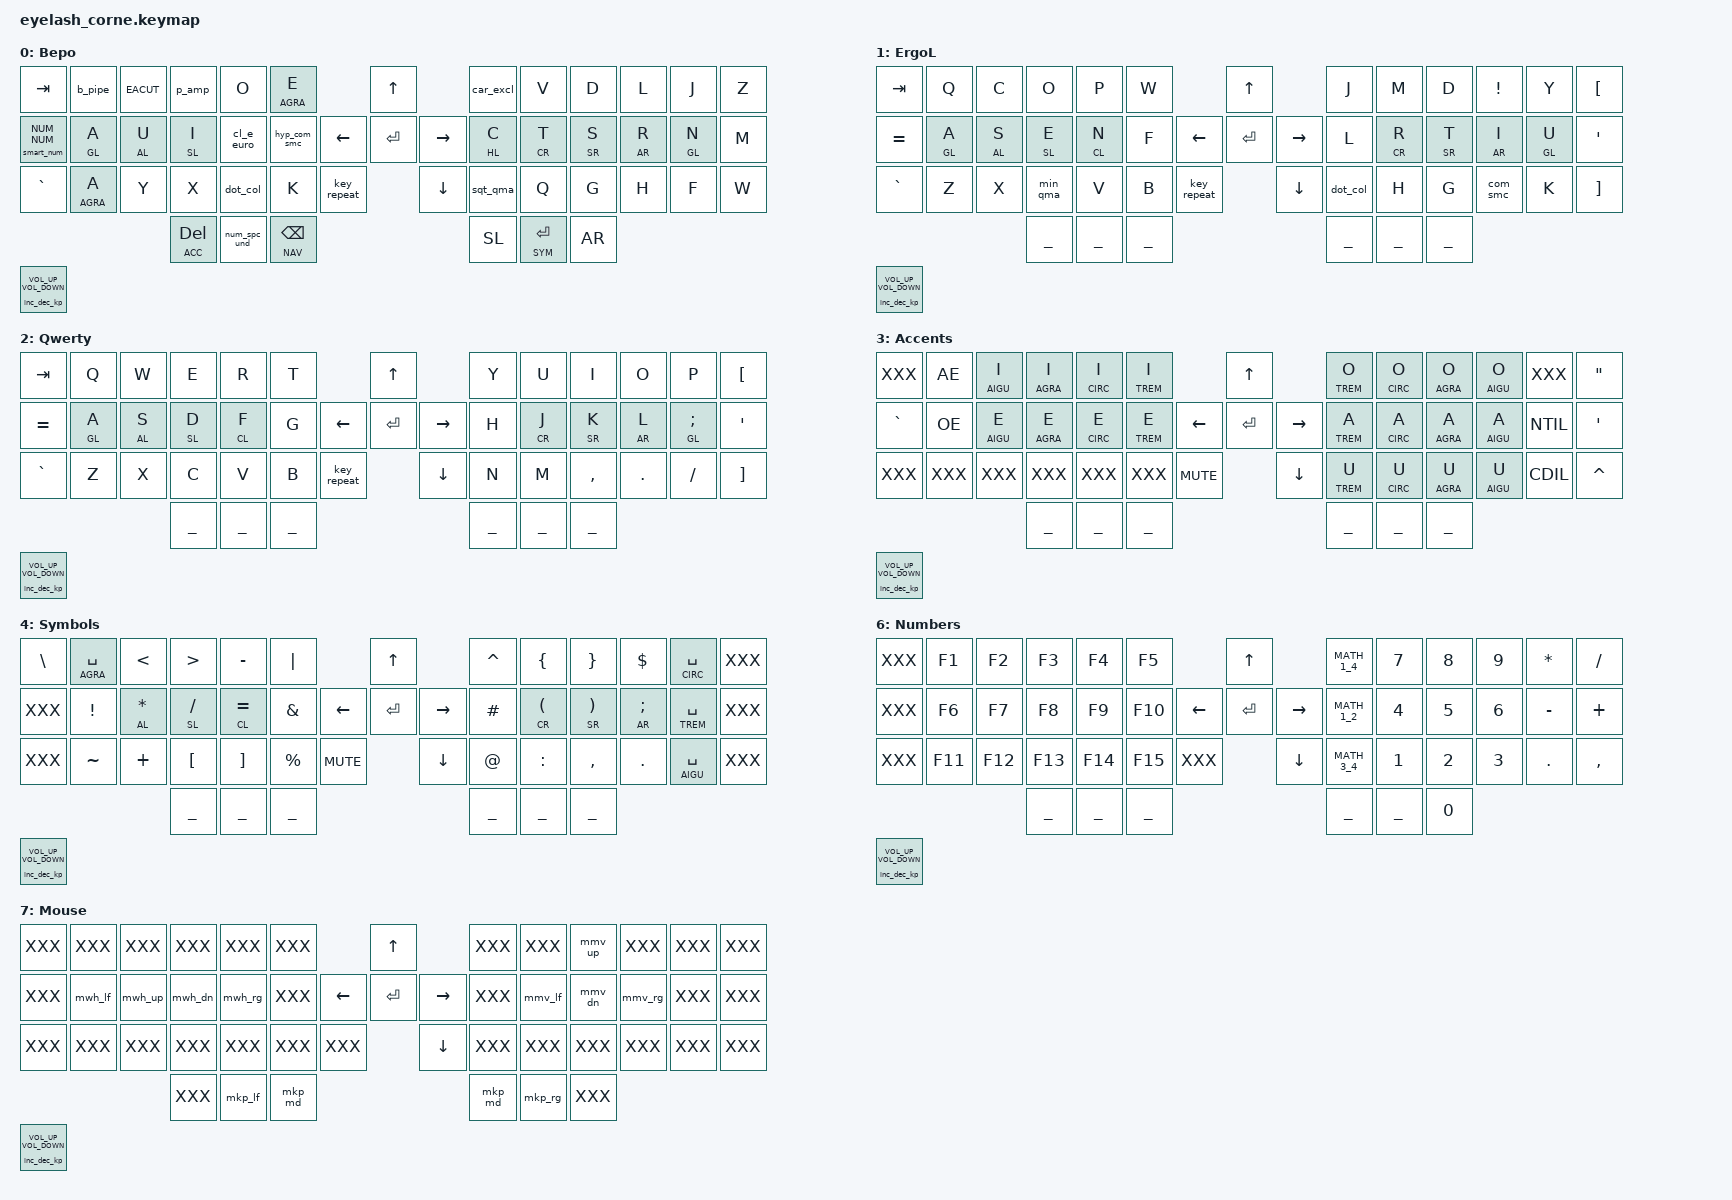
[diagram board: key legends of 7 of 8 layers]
#include <dt-bindings/zmk/mouse.h>
#include <input/processors.dtsi>
#include <behaviors.dtsi>
#include <dt-bindings/zmk/bt.h>
#include <dt-bindings/zmk/keys.h>
#include <dt-bindings/zmk/outputs.h>
#include <dt-bindings/zmk/pointing.h>
#include <dt-bindings/zmk/rgb.h>

#include "constants.h"
#define HOST_OS LINUX // Needed for unicode international_chars

#include "zmk-helpers/helper.h"
#include "zmk-helpers/key-labels/eyelash42.h"
#include "zmk-helpers/unicode-chars/currency.dtsi"
#include "zmk-helpers/unicode-chars/french.dtsi"
#include "combos.dtsi"
#include "leader.dtsi"
#include "numword.dtsi"
#include "hold-tap.dtsi"
#include "mod-morph.dtsi"
#include "mouse.dtsi"

#define ZMK_MOUSE_DEFAULT_MOVE_VAL 1200  // 600
#define ZMK_MOUSE_DEFAULT_SCRL_VAL 20    // 10
#define IDLE_MS 125


// 0: Bépo
// This is an "adaptation" of the bépo layout (https://bepo.fr/wiki/Accueil)
// There is some difference
// - No Ê or Ç keys, we don't have enough room
// - Not all RIGHT_ALT and RIGHT_ALT+SHIFT are available, as those might be accessed from a different layer instead, and some are very hard to do, like `…`
// - It works if the layout on the system (at least for that keyboard) is US_intl 😇. This is common enough (and available everywhere, Linux, Windows, OSX, Android, …)
// - TODO go to accent layer (and back)
ZMK_LAYER(Bepo,
// ╭───────────┬───────────┬───────────┬───────────┬────────────┬────────────╮                                ╭───────────┬─────────────┬─────────────┬────────────┬────────────┬────────────╮
     &kp TAB     &b_pipe     &kp EACUT   &p_amp      &kp O        &AGRA E                 &kp UP                &car_excl   &kp V         &kp D         &kp L        &kp J        &kp Z
// ├───────────┼───────────┼───────────┼───────────┼────────────┼────────────┤                                ├───────────┼─────────────┼─────────────┼────────────┼────────────┼────────────┤
     &smart_num NUM NUM   &hml GL A   &hml AL U   &hml SL I   &cl_e_euro   &hyp_com_smc  &kp LEFT  &kp RET  &kp RIGHT    &hmr HL C   &hmr CR T     &hmr SR S     &hmr AR R    &hmr GL N    &kp M
// ├───────────┼───────────┼───────────┼───────────┼────────────┼────────────┤                                ├───────────┼─────────────┼─────────────┼────────────┼────────────┼────────────┤
     &kp GRAVE   &AGRA A     &kp Y       &kp X       &dot_col     &kp K        &key_repeat &kp DOWN          &sqt_qma    &kp Q         &kp G         &kp H        &kp F        &kp W
// ╰───────────┴───────────────────────┼───────────┼────────────┼────────────┤                                ├───────────┼─────────────┼─────────────┼────────────┴────────────┴────────────╯
                                        &lt ACC DEL  &num_spc_und &lt NAV BSPC                                   &kp SL      &lt SYM RET   &kp AR
//                                     ╰───────────┴────────────┴────────────╯                                ╰───────────┴─────────────┴─────────────╯
	  , &inc_dec_kp C_VOLUME_UP C_VOLUME_DOWN
)

// 1: ErgoL
// This is an "adaptation" of the ergol layout (https://ergol.org/claviers/compacts/#kbd_3x6)
ZMK_LAYER(ErgoL,
// ╭───────────┬───────────┬───────────┬───────────┬────────────┬────────────╮                                ╭───────────┬─────────────┬─────────────┬────────────┬────────────┬────────────╮
     &kp TAB     &kp Q       &kp C       &kp O       &kp P        &kp  W                  &kp UP                &kp J       &kp M         &kp D         &kp EXCL     &kp Y        &kp LBKT
// ├───────────┼───────────┼───────────┼───────────┼────────────┼────────────┤                                ├───────────┼─────────────┼─────────────┼────────────┼────────────┼────────────┤
     &kp EQUAL   &hml GL A   &hml AL S   &hml SL E   &hml CL N    &kp F         &kp LEFT  &kp RET  &kp RIGHT    &kp L       &hmr CR R     &hmr SR T     &hmr AR I    &hmr GL U    &kp SQT
// ├───────────┼───────────┼───────────┼───────────┼────────────┼────────────┤                                ├───────────┼─────────────┼─────────────┼────────────┼────────────┼────────────┤
     &kp GRAVE   &kp Z       &kp X       &min_qma    &kp V        &kp B        &key_repeat &kp DOWN          &dot_col    &kp H         &kp G         &com_smc     &kp K        &kp RBKT
// ╰───────────┴───────────────────────┼───────────┼────────────┼────────────┤                                ├───────────┼─────────────┼─────────────┼────────────┴────────────┴────────────╯
                                         ___         ___          ___                                           ___         ___           ___
//                                     ╰───────────┴────────────┴────────────╯                                ╰───────────┴─────────────┴─────────────╯
	  , &inc_dec_kp C_VOLUME_UP C_VOLUME_DOWN
)

// 2: Qwerty
ZMK_LAYER(Qwerty,
// ╭───────────┬───────────┬───────────┬───────────┬────────────┬────────────╮                                ╭───────────┬─────────────┬─────────────┬────────────┬────────────┬────────────╮
     &kp TAB     &kp Q       &kp W       &kp E       &kp R        &kp T                   &kp UP                &kp Y       &kp U         &kp I         &kp O        &kp P        &kp LBKT
// ├───────────┼───────────┼───────────┼───────────┼────────────┼────────────┤                                ├───────────┼─────────────┼─────────────┼────────────┼────────────┼────────────┤
     &kp EQUAL   &hml GL A   &hml AL S   &hml SL D   &hml CL F    &kp G         &kp LEFT  &kp RET  &kp RIGHT    &kp H       &hmr CR J     &hmr SR K     &hmr AR L   &hmr GL SEMI  &kp SQT
// ├───────────┼───────────┼───────────┼───────────┼────────────┼────────────┤                                ├───────────┼─────────────┼─────────────┼────────────┼────────────┼────────────┤
     &kp GRAVE   &kp Z       &kp X       &kp C       &kp V        &kp B        &key_repeat &kp DOWN          &kp N       &kp M         &kp COMMA     &kp DOT      &kp FSLH     &kp RBKT
// ╰───────────┴───────────────────────┼───────────┼────────────┼────────────┤                                ├───────────┼─────────────┼─────────────┼────────────┴────────────┴────────────╯
                                         ___         ___          ___                                           ___         ___           ___
//                                     ╰───────────┴────────────┴────────────╯                                ╰───────────┴─────────────┴─────────────╯
	  , &inc_dec_kp C_VOLUME_UP C_VOLUME_DOWN
)

// 3: Accents
//  Â À Ê É È Ê Î Ê Ô Ê Û Ù Ê Æ Ç
ZMK_LAYER(Accents,
// ╭───────────┬───────────┬───────────┬───────────┬────────────┬────────────╮                                ╭───────────┬─────────────┬─────────────┬────────────┬────────────┬────────────╮
     XXX         &kp AE      &AIGU I     &AGRA I     &CIRC I      &TREM I                 &kp UP                &TREM O     &CIRC O       &AGRA O       &AIGU O      XXX          &kp DQT
// ├───────────┼───────────┼───────────┼───────────┼────────────┼────────────┤                                ├───────────┼─────────────┼─────────────┼────────────┼────────────┼────────────┤
     &kp GRAVE   &kp OE      &AIGU E     &AGRA E     &CIRC E      &TREM E       &kp LEFT  &kp RET  &kp RIGHT    &TREM A     &CIRC A       &AGRA A       &AIGU A      &kp NTIL     &kp SQT
// ├───────────┼───────────┼───────────┼───────────┼────────────┼────────────┤                                ├───────────┼─────────────┼─────────────┼────────────┼────────────┼────────────┤
     XXX         XXX         XXX         XXX         XXX          XXX          &kp C_MUTE &kp DOWN              &TREM U     &CIRC U       &AGRA U       &AIGU U      &kp CDIL     &kp CARET
// ╰───────────┴───────────────────────┼───────────┼────────────┼────────────┤                                ├───────────┼─────────────┼─────────────┼────────────┴────────────┴────────────╯
                                         ___         ___          ___                                           ___         ___           ___
//                                     ╰───────────┴────────────┴────────────╯                                ╰───────────┴─────────────┴─────────────╯
	  , &inc_dec_kp C_VOLUME_UP C_VOLUME_DOWN
)

// 4: SYMBOLS
ZMK_LAYER(Symbols,
// ╭───────────┬───────────┬───────────┬───────────┬────────────┬────────────╮                                ╭───────────┬─────────────┬─────────────┬────────────┬────────────┬────────────╮
     &kp BSLH    &AGRA SPACE  &kp LT      &kp GT      &kp MINUS    &kp PIPE                &kp UP                &kp CARET   &kp LBRC      &kp RBRC      &kp DLLR     &CIRC SPACE  XXX
// ├───────────┼───────────┼───────────┼───────────┼────────────┼────────────┤                                ├───────────┼─────────────┼─────────────┼────────────┼────────────┼────────────┤
     XXX         &kp EXCL &hml AL STAR &hml SL FSLH &hml CL EQUAL &kp AMPS      &kp LEFT  &kp RET  &kp RIGHT    &kp HASH   &hmr CR LPAR  &hmr SR RPAR  &hmr AR SEMI  &TREM SPACE  XXX
// ├───────────┼───────────┼───────────┼───────────┼────────────┼────────────┤                                ├───────────┼─────────────┼─────────────┼────────────┼────────────┼────────────┤
     XXX         &kp TILDE   &kp PLUS    &kp LBKT    &kp RBKT     &kp PRCNT    &kp C_MUTE &kp DOWN              &kp AT      &kp COLON     &kp COMMA     &kp DOT      &AIGU SPACE  XXX
// ╰───────────┴───────────────────────┼───────────┼────────────┼────────────┤                                ├───────────┼─────────────┼─────────────┼────────────┴────────────┴────────────╯
                                         ___         ___          ___                                           ___         ___           ___
//                                     ╰───────────┴────────────┴────────────╯                                ╰───────────┴─────────────┴─────────────╯
	  , &inc_dec_kp C_VOLUME_UP C_VOLUME_DOWN
)

// 5: Navigation
ZMK_LAYER(Nav,
// ╭───────────┬───────────┬───────────┬───────────┬────────────┬────────────╮                                ╭───────────┬─────────────┬─────────────┬────────────┬────────────┬────────────╮
    &out OUT_TOG XXX         XXX         XXX         XXX          &bt BT_CLR              &mmv_up             &kp PRINTSCREEN &kp HOME      &kp UP        &kp END      &kp PG_UP    XXX
// ├───────────┼───────────┼───────────┼───────────┼────────────┼────────────┤                                ├───────────┼─────────────┼─────────────┼────────────┼────────────┼────────────┤
     XXX         &kp GL      &kp C_PREV  &kp C_PP    &kp C_NEXT   XXX          &mmv_lf    &mkp_lf  &mmv_rg      XXX         &kp LEFT      &kp DOWN      &kp RIGHT    &kp PG_DN    XXX
// ├───────────┼───────────┼───────────┼───────────┼────────────┼────────────┤                                ├───────────┼─────────────┼─────────────┼────────────┼────────────┼────────────┤
     XXX         &bt BT_PRV  &bt BT_NXT &rgb_ug RGB_TOG &rgb_ug RGB_EFF &rgb_ug RGB_COLOR_HSB(205, 66, 57) &kp C_MUTE &mmv_dn           XXX         XXX           XXX           XXX          XXX          XXX
// ╰───────────┴───────────────────────┼───────────┼────────────┼────────────┤                                ├───────────┼─────────────┼─────────────┼────────────┴────────────┴────────────╯
                                         ___         ___          ___                                           ___         ___           ___
//                                     ╰───────────┴────────────┴────────────╯                                ╰───────────┴─────────────┴─────────────╯
	  , &inc_dec_kp C_BRI_INC C_BRI_DEC
)

// 6: Numbers
ZMK_LAYER(Numbers,
// ╭───────────┬───────────┬───────────┬───────────┬────────────┬────────────╮                                ╭───────────┬─────────────┬─────────────┬────────────┬────────────┬────────────╮
     XXX         &kp F1      &kp F2      &kp F3      &kp F4      &kp F5                   &kp UP               &kp MATH_1_4 &kp N7        &kp N8       &kp N9        &kp STAR     &kp SLASH
// ├───────────┼───────────┼───────────┼───────────┼────────────┼────────────┤                                ├───────────┼─────────────┼─────────────┼────────────┼────────────┼────────────┤
     XXX         &kp F6      &kp F7      &kp F8      &kp F9      &kp F10        &kp LEFT  &kp RET  &kp RIGHT   &kp MATH_1_2 &kp N4        &kp N5       &kp N6        &kp MINUS    &kp PLUS
// ├───────────┼───────────┼───────────┼───────────┼────────────┼────────────┤                                ├───────────┼─────────────┼─────────────┼────────────┼────────────┼────────────┤
     XXX         &kp F11     &kp F12     &kp F13     &kp F14     &kp F15        XXX       &kp DOWN             &kp MATH_3_4 &kp N1        &kp N2       &kp N3        &kp DOT      &kp COMMA
// ╰───────────┴───────────────────────┼───────────┼────────────┼────────────┤                                ├───────────┼─────────────┼─────────────┼────────────┴────────────┴────────────╯
                                         ___         ___          ___                                           ___         ___           &kp N0
//                                     ╰───────────┴────────────┴────────────╯                                ╰───────────┴─────────────┴─────────────╯
	  , &inc_dec_kp C_VOLUME_UP C_VOLUME_DOWN
)

// 7: Mouse
ZMK_LAYER(Mouse,
// ╭───────────┬───────────┬───────────┬───────────┬────────────┬────────────╮                                ╭───────────┬─────────────┬─────────────┬────────────┬────────────┬────────────╮
     XXX         XXX         XXX         XXX         XXX          XXX                     &kp UP                XXX         XXX           &mmv_up       XXX          XXX          XXX
// ├───────────┼───────────┼───────────┼───────────┼────────────┼────────────┤                                ├───────────┼─────────────┼─────────────┼────────────┼────────────┼────────────┤
     XXX         &mwh_lf     &mwh_up     &mwh_dn     &mwh_rg      XXX           &kp LEFT  &kp RET  &kp RIGHT    XXX         &mmv_lf       &mmv_dn       &mmv_rg      XXX         XXX
// ├───────────┼───────────┼───────────┼───────────┼────────────┼────────────┤                                ├───────────┼─────────────┼─────────────┼────────────┼────────────┼────────────┤
     XXX         XXX         XXX         XXX         XXX          XXX           XXX       &kp DOWN              XXX         XXX           XXX           XXX          XXX          XXX
// ╰───────────┴───────────────────────┼───────────┼────────────┼────────────┤                                ├───────────┼─────────────┼─────────────┼────────────┴────────────┴────────────╯
                                         XXX         &mkp_lf      &mkp_md                                       &mkp_md     &mkp_rg       XXX
//                                     ╰───────────┴────────────┴────────────╯                                ╰───────────┴─────────────┴─────────────╯
	  , &inc_dec_kp C_VOLUME_UP C_VOLUME_DOWN
)
/*

/*
Local Variables:
mode: c
End:
*/
